# ATA5700M322 device description
Architecture: AVR8; Family: megaAVR
Registers are 8-bit, access not given, no defined reset value unless marked. A register's access mark holds for its fields unless they carry their own. Offsets are from the block's base; [hi:lo] are bit positions; {n}, {i} and the like mark numbered series.

## AES
Instances: AES 0x00
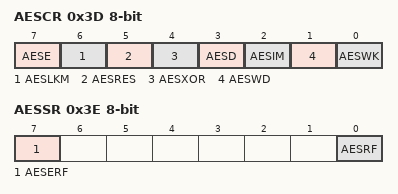
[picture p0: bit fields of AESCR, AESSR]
0x3D AESCR — AES Control Register
  [7] AESE — AES Enable
  [6] AESLKM — AES Load Key Memory
  [5] AESRES — AES Reset
  [4] AESXOR — AES State XOR load
  [3] AESD — AES Direction
  [2] AESIM — AES Interrupt Mask
  [1] AESWD — AES Write Data
  [0] AESWK — AES Write Key
0x3E AESSR — AES Status Register
  [7] AESERF — AES Error Flag
  [0] AESRF — AES Ready Flag
0x17F AESDPR bits used 3:0 — AES Data Pointer Register
0x180 AESKR — AES Key Register
0x181 AESDR — AES Data Register

## CLK
Instances: CLK 0x00
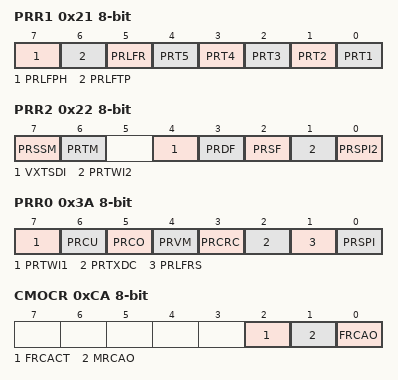
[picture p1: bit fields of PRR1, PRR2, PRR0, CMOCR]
0x21 PRR1 — Power reduction Register 1
  [7] PRLFPH — Power Reduction LF Protocol Handler
  [6] PRLFTP — Power Reduction LF Transponder
  [5] PRLFR — Power Reduction LF Receiver
  [n-1] PRT{n} (n=1..5) — Power Reduction Timer {n}
0x22 PRR2 — Power reduction register 2
  [7] PRSSM — Power Reduction Sequencer State Machine
  [6] PRTM — Power Reduction Tx Modulator
  [4] VXTSDI — VX Tri-State Disable
  [3] PRDF — Power Reduction Data FIFO
  [2] PRSF — Power Reduction Support FIFO
  [1] PRTWI2 — Power Reduction TWI2
  [0] PRSPI2 — Power Reduction SPI2
0x3A PRR0 — Power reduction Register 0
  [7] PRTWI1 — Power Reduction Two Wire Interface 1
  [6] PRCU — Power Reduction Crypto Unit
  [5] PRCO — Power Reduction Clock Output
  [4] PRVM — Power Reduction Voltage Monitor
  [3] PRCRC — Power Reduction CRC
  [2] PRTXDC — Power Reduction Transmit DSP Control
  [1] PRLFRS — Power Reduction LF RSSI
  [0] PRSPI — Power Reduction Serial Peripheral Interface
0xC5 XFUSE
0xC6 MRCCAL bits used 7:1 — Middle RC oscillator calibration Register
0xC7 FRCCAL bits used 4:0 — Fast RC oscillator calibration Register
0xC9 CMSR — Clock management status Register
  [0] ECF — External clock fail
0xCA CMOCR — Clock management override control register
  [2] FRCACT — FRC Active
  [1] MRCAO — MRC Always On
  [0] FRCAO — FRC Always On
0x115 CLKOD — Clock output divider settings Register
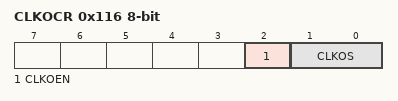
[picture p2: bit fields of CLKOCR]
0x116 CLKOCR — Clock output control Register
  [2] CLKOEN — Clock output driver enable
  [1:0] CLKOS — Clock output source
    0=clk_src; 1=clk_frc; 2=clk_mrc; 3=clk_xto

## CPU
Instances: CPU 0x00
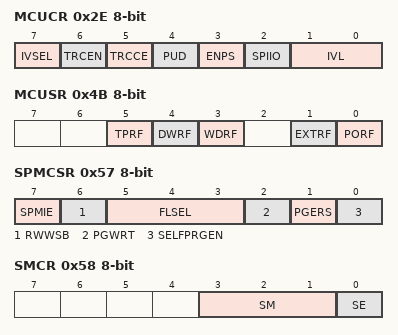
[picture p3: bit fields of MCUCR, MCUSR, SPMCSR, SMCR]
0x2E MCUCR — MCU control Register
  [7] IVSEL — Interrupt Vector Select
  [6] TRCEN — Trace Enable
  [5] TRCCE — Trace Change Enable
  [4] PUD — Pull-up Resistors Disable
  [3] ENPS — Enable Port Settings
  [2] SPIIO — SPI Interrupt Only
  [1:0] IVL — Interrupt Vector Location
    0=0x3600; 1=0x4000; 2=0x7000; 3=0x8000
0x4B MCUSR — MCU Status Register
  [5] TPRF — Transponder Reset Flag
  [4] DWRF — DebugWire Reset Flag
  [3] WDRF — Watchdog Reset Flag
  [1] EXTRF — External Reset Flag
  [0] PORF — Power-On Reset Flag
0x51 DWDR — Debug Wire Data Register
0x57 SPMCSR — Store Program Memory Control and Status Register
  [7] SPMIE — SPM Interrupt Enable
  [6] RWWSB — Read-While-Write Section Busy
  [5:3] FLSEL — Fuse Lockbit select
    0=ROM/FLASH; 8=Lockbits; 24=Security Fuses; 40=EEPROM Protection Fuse Low; 56=VALR_0x07 (EEPROM Protection Fuse High)
  [2] PGWRT — Page Write
  [1] PGERS — Page Erase
  [0] SELFPRGEN — Self Programming Enable
0x58 SMCR — Sleep mode control Register
  [3:1] SM — Sleep Mode Select
    0=IDLE; 1=PSAVE (Power save); 2=EPSAVE (Extended power save); 3=PDOWN (Power down); 4=EPDOWN (Extended power down); 5=POFF (Power off)
  [0] SE — Sleep Enable
0x5D SP 16-bit bits used 10:0 — Stack Pointer
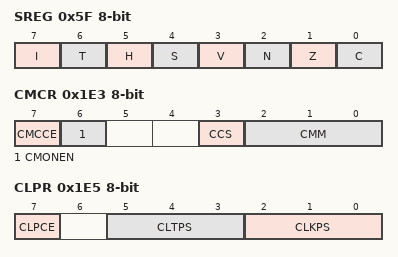
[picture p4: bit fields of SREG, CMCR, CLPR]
0x5F SREG — Status Register
  [7] I — Global Interrupt Enable
  [6] T — Bit Copy Storage
  [5] H — Half Carry Flag
  [4] S — Sign Bit
  [3] V — Two's Complement Overflow Flag
  [2] N — Negative Flag
  [1] Z — Zero Flag
  [0] C — Carry Flag
0x1E3 CMCR — Clock Management Control Register
  [7] CMCCE — Clock management control change enable
  [6] CMONEN — Clock monitor enable
  [3] CCS — Core Clock Select
  [2:0] CMM — Clock Management Mode
0x1E4 CMIMR — Clock interrupt mask Register
  [0] ECIE — External clock interrupt enable
0x1E5 CLPR — Clock Prescaler Register
  [7] CLPCE — Clock Prescaler Change Enable
  [5:3] CLTPS — Timer Clock Prescaler Select
    0=disabled; 1=1; 2=2; 3=4; 4=8; 5=16; 6=32; 7=64
  [2:0] CLKPS — System Clock Prescaler Select
    0=1; 1=2; 2=4; 3=8; 4=16; 5=32; 6=64; 7=128
